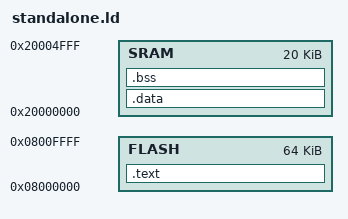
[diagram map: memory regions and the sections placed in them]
/******************************************************************************
 *
 * standalone.ld - Linker script for applications using startup.c and
 *                 DriverLib.
 *
 * Copyright (c) 2005-2007 Luminary Micro, Inc.  All rights reserved.
 * 
 * Software License Agreement
 * 
 * Luminary Micro, Inc. (LMI) is supplying this software for use solely and
 * exclusively on LMI's microcontroller products.
 * 
 * The software is owned by LMI and/or its suppliers, and is protected under
 * applicable copyright laws.  All rights are reserved.  Any use in violation
 * of the foregoing restrictions may subject the user to criminal sanctions
 * under applicable laws, as well as to civil liability for the breach of the
 * terms and conditions of this license.
 * 
 * THIS SOFTWARE IS PROVIDED "AS IS".  NO WARRANTIES, WHETHER EXPRESS, IMPLIED
 * OR STATUTORY, INCLUDING, BUT NOT LIMITED TO, IMPLIED WARRANTIES OF
 * MERCHANTABILITY AND FITNESS FOR A PARTICULAR PURPOSE APPLY TO THIS SOFTWARE.
 * LMI SHALL NOT, IN ANY CIRCUMSTANCES, BE LIABLE FOR SPECIAL, INCIDENTAL, OR
 * CONSEQUENTIAL DAMAGES, FOR ANY REASON WHATSOEVER.
 * 
 * This is part of revision 1392 of the Stellaris Peripheral Driver Library.
 *
 *****************************************************************************/

/* Linker script for the STM32F103C8T6 */
/* Copy from stm32f1xx_hal rs */
MEMORY
{
  FLASH : ORIGIN = 0x08000000, LENGTH = 64K
  SRAM : ORIGIN = 0x20000000, LENGTH = 20K
}

ENTRY(reset_handler)

SECTIONS
{
    .text :
    {
        . = ALIGN(4);
        KEEP(*(.isr_vector))
        *(.text*)
        *(.rodata*)
        . = ALIGN(4);
        _etext = .;
    } > FLASH

    .data :
    {
        . = ALIGN(4);
        _data = .;
        *(vtable)
        *(.data*)
        . = ALIGN(4);
        _edata = .;
    } > SRAM

    .bss :
    {
        . = ALIGN(4);
        _bss = .;
        *(.bss*)
        *(COMMON)
          . = ALIGN(4);
        _ebss = .;
    } > SRAM
}
